# STM32G071 register map
File version: 2.5
CPU: CM0 r0p1, little endian, MPU, no FPU, 2 interrupt priority bits
Registers are 32-bit, read-write, reset 0x0 unless marked. A register's access mark holds for its fields unless they carry their own. Offsets are from the block's base; [hi:lo] are bit positions; {n}, {i} and the like mark numbered series.

## WWDG — System window watchdog
Base 0x40002C00
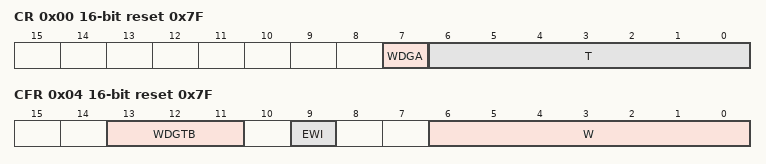
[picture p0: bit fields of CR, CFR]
0x00 CR 16-bit reset 0x7F — Control register
  [7] WDGA — Activation bit
    0=Disabled (Watchdog disabled); 1=Enabled (Watchdog enabled)
  [6:0] T — 7-bit counter (MSB to LSB)
0x04 CFR 16-bit reset 0x7F — Configuration register
  [13:11] WDGTB — Timer base
    0=Div1 (Counter clock (PCLK1 div 4096) div 1); 1=Div2 (Counter clock (PCLK1 div 4096) div 2); 2=Div4 (Counter clock (PCLK1 div 4096) div 4); 3=Div8 (Counter clock (PCLK1 div 4096) div 8); 4=Div16 (Counter clock (PCLK1 div 4096) div 16); 5=Div32 (Counter clock (PCLK1 div 4096) div 32); 6=Div64 (Counter clock (PCLK1 div 4096) div 64); 7=Div128 (Counter clock (PCLK1 div 4096) div 128)
  [9] EWI — Early wakeup interrupt
    on write: 1=Enable (interrupt occurs whenever the counter reaches the value 0x40)
  [6:0] W — 7-bit window value
0x08 SR 16-bit — Status register
  [0] EWIF write-0-clears — Early wakeup interrupt flag
    on read: 0=Finished (The EWI Interrupt Service Routine has been serviced); 1=Pending (The EWI Interrupt Service Routine has been triggered) | on write: 0=Finished (The EWI Interrupt Service Routine has been serviced)

## DBG — Debug support
Base 0x40015800
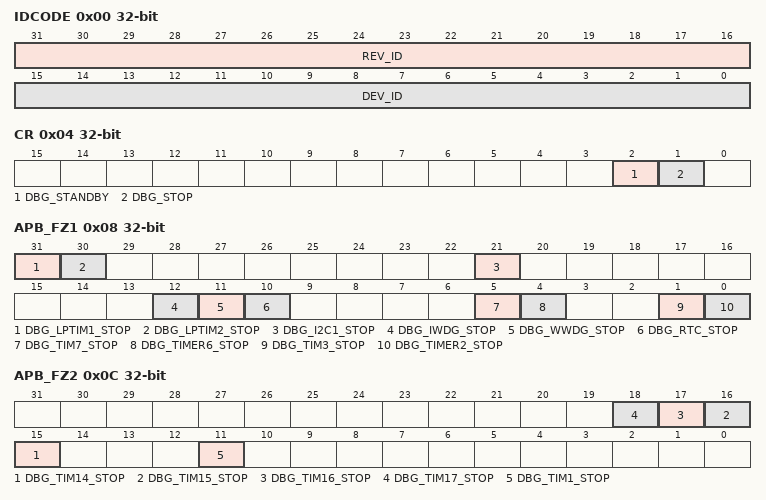
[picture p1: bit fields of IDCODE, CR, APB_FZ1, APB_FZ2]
0x00 IDCODE ro — MCU Device ID Code Register
  [31:16] REV_ID — Revision Identifier
  [15:0] DEV_ID — Device Identifier
0x04 CR — Debug MCU Configuration Register
  [2] DBG_STANDBY — Debug Standby Mode
  [1] DBG_STOP — Debug Stop Mode
0x08 APB_FZ1 — DBG APB freeze register 1
  [31] DBG_LPTIM1_STOP — Clocking of LPTIMER1 counter when the core is halted
  [30] DBG_LPTIM2_STOP — Clocking of LPTIMER2 counter when the core is halted
  [21] DBG_I2C1_STOP — I2C1 SMBUS timeout mode stopped when core is halted
  [12] DBG_IWDG_STOP — Debug Independent Wachdog stopped when Core is halted
  [11] DBG_WWDG_STOP — Debug Window Wachdog stopped when Core is halted
  [10] DBG_RTC_STOP — Debug RTC stopped when Core is halted
  [5] DBG_TIM7_STOP — TIM7 counter stopped when core is halted
  [4] DBG_TIMER6_STOP — Debug Timer 6 stopped when Core is halted
  [1] DBG_TIM3_STOP — TIM3 counter stopped when core is halted
  [0] DBG_TIMER2_STOP — Debug Timer 2 stopped when Core is halted
0x0C APB_FZ2 — DBG APB freeze register 2
  [n+1] DBG_TIM{n}_STOP (n=14..17), [11] DBG_TIM1_STOP

## GPIOA — General-purpose I/Os
Base 0x50000000
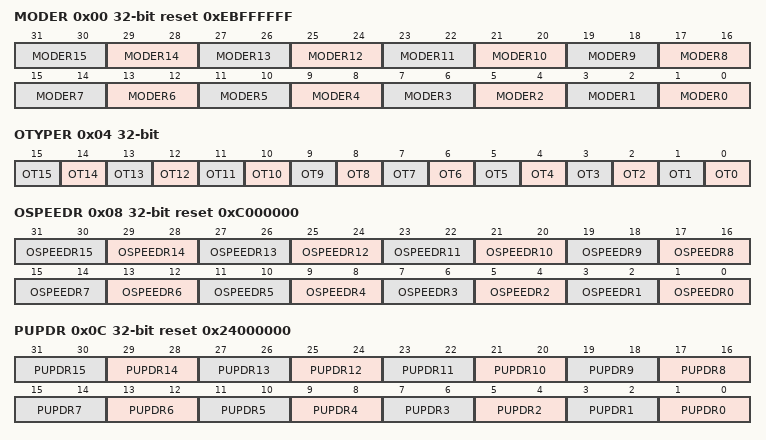
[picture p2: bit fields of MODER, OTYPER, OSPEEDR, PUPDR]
0x00 MODER reset 0xEBFFFFFF — GPIO port mode register
  [2n+1:2n] MODER{n} (n=0..15) — Port x configuration pin {n}
    0=Input mode; 1=Output (General purpose output mode); 2=Alternate function mode; 3=Analog mode
0x04 OTYPER — GPIO port output type register
  [n] OT{n} (n=0..15) — Port x configuration pin {n}
    0=PushPull (Output push-pull (reset state)); 1=OpenDrain (Output open-drain)
0x08 OSPEEDR reset 0xC000000 — GPIO port output speed register
  [2n+1:2n] OSPEEDR{n} (n=0..15) — Port x configuration pin {n}
    0=LowSpeed; 1=MediumSpeed; 2=HighSpeed; 3=VeryHighSpeed
0x0C PUPDR reset 0x24000000 — GPIO port pull-up/pull-down register
  [2n+1:2n] PUPDR{n} (n=0..15) — Port x configuration pin {n}
    0=Floating (No pull-up, pull-down); 1=PullUp; 2=PullDown
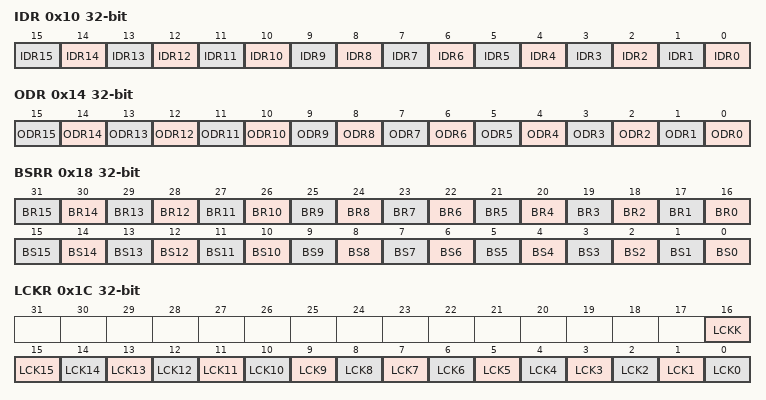
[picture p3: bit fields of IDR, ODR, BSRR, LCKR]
0x10 IDR ro — GPIO port input data register
  [n] IDR{n} (n=0..15) — Port input data pin {n}
    0=Low (Input is logic low); 1=High (Input is logic high)
0x14 ODR — GPIO port output data register
  [n] ODR{n} (n=0..15) — Port output data pin {n}
    0=Low (Set output to logic low); 1=High (Set output to logic high)
0x18 BSRR wo — GPIO port bit set/reset register
  [n+16] BR{n} (n=0..15) — Port x reset pin {n}
    1=Resets the corresponding ODx bit
  [n] BS{n} (n=0..15) — Port x set pin {n}
    1=Set (Sets the corresponding ODx bit)
0x1C LCKR — GPIO port configuration lock register
  [16] LCKK — Port x lock bit y (y= 0..15)
    0=NotActive (Port configuration lock key not active); 1=Active (Port configuration lock key active)
  [n] LCK{n} (n=0..15) — Port x lock pin {n}
    0=Unlocked (Port configuration not locked); 1=Locked (Port configuration locked)
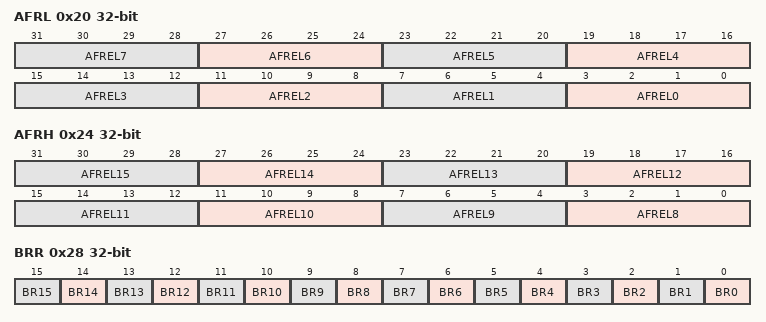
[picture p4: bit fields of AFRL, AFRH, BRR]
0x20 AFRL — GPIO alternate function low register
  [3:0] AFR{x} (x=EL0,EL1,EL2,EL3,EL4,EL5,EL6,EL7; step 4) — Alternate function selection for port x bit y (y = 0..7)
    {v}=AF{v} (v=0..7)
0x24 AFRH — GPIO alternate function high register
  [3:0] AFR{x} (x=EL8,EL9,EL10,EL11,EL12,EL13,EL14,EL15; step 4) — Alternate function selection for port x bit y (y = 8..15)
    {v}=AF{v} (v=0..7)
0x28 BRR wo — port bit reset register
  [n] BR{n} (n=0..15) — Port x reset pin {n}
    0=No action on the corresponding ODx bit; 1=Reset the ODx bit

## GPIOB — General-purpose I/Os
Base 0x50000400
Same registers: GPIOC 0x50000800, GPIOD 0x50000C00, GPIOF 0x50001400
Registers as GPIOA; these are added or differ:
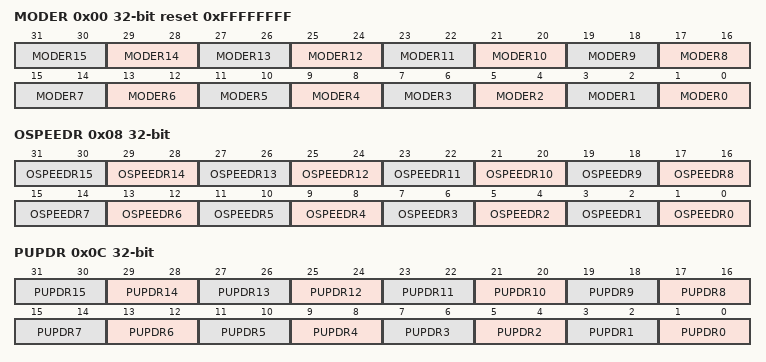
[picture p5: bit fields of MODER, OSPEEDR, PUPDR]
0x00 MODER reset 0xFFFFFFFF — GPIO port mode register
  [2n+1:2n] MODER{n} (n=0..15) — Port x configuration pin {n}
    0=Input mode; 1=Output (General purpose output mode); 2=Alternate function mode; 3=Analog mode
0x08 OSPEEDR — GPIO port output speed register
  [2n+1:2n] OSPEEDR{n} (n=0..15) — Port x configuration pin {n}
    0=LowSpeed; 1=MediumSpeed; 2=HighSpeed; 3=VeryHighSpeed
0x0C PUPDR — GPIO port pull-up/pull-down register
  [2n+1:2n] PUPDR{n} (n=0..15) — Port x configuration pin {n}
    0=Floating (No pull-up, pull-down); 1=PullUp; 2=PullDown
